# CY8C5888LTI_LP097 register map
File version: 0.1
CY8C58LP
Registers are 8-bit, read-write, no defined reset value unless marked. A register's access mark holds for its fields unless they carry their own. Offsets are from the block's base; lines under a group give offsets from that group; [hi:lo] are bit positions; {n}, {i} and the like mark numbered series; 'fields as' and 'values as' point back to an identical list; <NAME> marks a mode.

## Memory map
0x00000000 POT_VALUE — SAR ADC
0x00000000 Lights_Out_1_BUCK_DUTY
0x00000000 USB — USBFS
0x00000000 SleepTimer
0x00000000 RAMP_COMP
0x00000000 TRIANGLE_SEL_VDAC8
0x00000000 BRIGHTNESS_RAMP_VDAC8
0x40006467 CROSSFADE_VAL
0x40006469 Lights_Out_1_LED_STATUS
0x40006470 LIGHT_BRIGHTNESS_1
0x40006472 Lights_Out_1_LIGHT_COUNTER — Count7 debug registers
0x40006474 LIGHT_BRIGHTNESS_7
0x40006476 LIGHT_BRIGHTNESS_3
0x40006479 SLED_STATE_SEL
0x4000647B LIGHT_BRIGHTNESS_6
0x4000647D LIGHT_BRIGHTNESS_5
0x40006574 CROSSFADE_CTRL
0x40006576 LIGHT_BRIGHTNESS_2
0x40006578 LIGHT_BRIGHTNESS_4
0x4000657B HOT_LEDS

## CROSSFADE_VAL
Base 0x40006467
0x00 CROSSFADE_VAL_STATUS_REG
0x20 CROSSFADE_VAL_MASK_REG
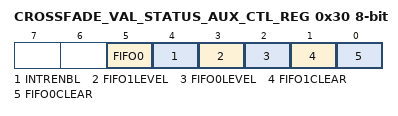
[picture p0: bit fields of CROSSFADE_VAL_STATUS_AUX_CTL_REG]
0x30 CROSSFADE_VAL_STATUS_AUX_CTL_REG
  [5] FIFO0 — FIFO0 clear
    1=ENABLED (Enable counter); 0=DISABLED (Disable counter)
  [4] INTRENBL — Enables or disables the Interrupt
    1=ENABLED (Interrupt enabled); 0=DISABLED (Interrupt disabled)
  [3] FIFO1LEVEL — FIFO level
    1=ENABLED (FIFO LVL: input mode: FIFO at least 1/2 empty; output mode: FIFO at least 1/2 full); 0=DISABLED (FIFO LVL: input mode: FIFO not full; output mode: FIFO not empty)
  [2] FIFO0LEVEL — FIFO level
    values as FIFO1LEVEL
  [1] FIFO1CLEAR — FIFO clear
    1=ENABLED (Clear FIFO state); 0=DISABLED (Normal FIFO operation)
  [0] FIFO0CLEAR — FIFO clear
    values as FIFO1CLEAR

## Lights_Out_1_LED_STATUS
Base 0x40006469
Registers as CROSSFADE_VAL (with CROSSFADE_VAL read as Lights_Out_1_LED_STATUS).

## POT_VALUE — SAR ADC
Base 0x00000000
0x40004614 SAR_TR0 — SAR trim register
{0x40005900+i} SAR_CSR{i} (i=0..6) — SAR status and control register {i}
0x40005B20 SAR_SW0 — SAR Analog Routing Register 0
{0x40005B20+i} SAR_SW{i} (i=2..4) — SAR Analog Routing Register {i}
0x40005B26 SAR_SW6 — SAR Analog Routing Register 6
0x40005B27 SAR_CLK — SAR Clock Selection Register
0x40005BA0 SAR_WRK 16-bit — SAR working register

## LIGHT_BRIGHTNESS_1
Base 0x40006470
0x00 LIGHT_BRIGHTNESS_1_CONTROL_REG

## LIGHT_BRIGHTNESS_2
Base 0x40006576
Registers as LIGHT_BRIGHTNESS_1 (with LIGHT_BRIGHTNESS_1 read as LIGHT_BRIGHTNESS_2).

## LIGHT_BRIGHTNESS_3
Base 0x40006476
Registers as LIGHT_BRIGHTNESS_1 (with LIGHT_BRIGHTNESS_1 read as LIGHT_BRIGHTNESS_3).

## LIGHT_BRIGHTNESS_4
Base 0x40006578
Registers as LIGHT_BRIGHTNESS_1 (with LIGHT_BRIGHTNESS_1 read as LIGHT_BRIGHTNESS_4).

## LIGHT_BRIGHTNESS_5
Base 0x4000647D
Registers as LIGHT_BRIGHTNESS_1 (with LIGHT_BRIGHTNESS_1 read as LIGHT_BRIGHTNESS_5).

## LIGHT_BRIGHTNESS_6
Base 0x4000647B
Registers as LIGHT_BRIGHTNESS_1 (with LIGHT_BRIGHTNESS_1 read as LIGHT_BRIGHTNESS_6).

## LIGHT_BRIGHTNESS_7
Base 0x40006474
Registers as LIGHT_BRIGHTNESS_1 (with LIGHT_BRIGHTNESS_1 read as LIGHT_BRIGHTNESS_7).

## CROSSFADE_CTRL
Base 0x40006574
Registers as LIGHT_BRIGHTNESS_1 (with LIGHT_BRIGHTNESS_1 read as CROSSFADE_CTRL).

## HOT_LEDS
Base 0x4000657B
Registers as LIGHT_BRIGHTNESS_1 (with LIGHT_BRIGHTNESS_1 read as HOT_LEDS).

## SLED_STATE_SEL
Base 0x40006479
Registers as LIGHT_BRIGHTNESS_1 (with LIGHT_BRIGHTNESS_1 read as SLED_STATE_SEL).

## Lights_Out_1_LIGHT_COUNTER — Count7 debug registers
Base 0x40006472
0x00 COUNT 7-bit — Count value register
0x10 PERIOD 7-bit — Count7 period register

## Lights_Out_1_BUCK_DUTY
Base 0x00000000
0x400043A3 Lights_Out_1_BUCK_DUTY_GLOBAL_ENABLE — PM.ACT.CFG
  [3:0] en_timer — Enable timer/counters.
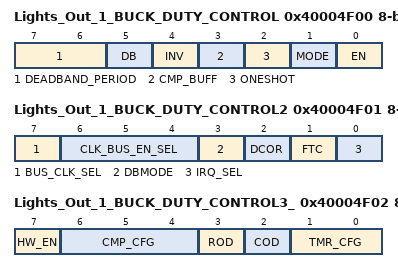
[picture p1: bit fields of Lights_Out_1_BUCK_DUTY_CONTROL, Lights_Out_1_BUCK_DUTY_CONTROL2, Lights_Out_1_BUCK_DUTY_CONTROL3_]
0x40004F00 Lights_Out_1_BUCK_DUTY_CONTROL — TMRx.CFG0
  [7:6] DEADBAND_PERIOD
  [5] DB — Deadband mode--Deadband phases phi1 and phi2 are outputted on CMP and TC output pins respectively.
    0=Timer (CMP and TC are output.); 1=Deadband (PHI1 (instead of CMP) and PHI2 (instead of TC) are output.)
  [4] INV — Invert sense of TIMEREN signal
  [3] CMP_BUFF — Buffer compare register. Compare register updates only on timer terminal count.
  [2] ONESHOT — Timer stops upon reaching stop condition defined by TMR_CFG bits. Can be restarted by asserting TIMER RESET or disabling and re-enabling block.
  [1] MODE — Mode. (0 = Timer; 1 = Comparator)
    0=Timer mode. CNT/CMP register holds timer count value.; 1=Comparator mode. CNT/CMP register holds comparator threshold value.
  [0] EN — Enables timer/comparator.
0x40004F01 Lights_Out_1_BUCK_DUTY_CONTROL2 — TMRx.CFG1
  [7] BUS_CLK_SEL — Bus Clock selection.
  [6:4] CLK_BUS_EN_SEL — Digital Global Clock selection.
  [3] DBMODE — Deadband mode (asynchronous/synchronous). CMP output pin is also affected when not in deadband mode (CFG0.DEADBAND).
  [2] DCOR — Disable Clear on Read (DCOR) of Status Register SR0.
  [1] FTC — First Terminal Count (FTC). Setting this bit forces a single pulse on the TC pin when first enabled.
    0=Disable_FTC (Disable the single cycle pulse, which signifies the timer is starting.); 1=Enable_FTC (Enable the single cycle pulse, which signifies the timer is starting.)
  [0] IRQ_SEL — Irq selection. (0 = raw interrupts; 1 = status register interrupts)
0x40004F02 Lights_Out_1_BUCK_DUTY_CONTROL3_ — TMRx.CFG2
  [7] HW_EN — When set Timer Enable controls counting.
  [6:4] CMP_CFG — Comparator configurations
    0=Equal (Compare Equal); 1=Less_than (Compare Less Than); 2=Less_than_or_equal (Compare Less Than or Equal .); 3=Greater (Compare Greater Than .); 4=Greater_than_or_equal (Compare Greater Than or Equal)
  [3] ROD — Reset On Disable (ROD). Resets internal state of output logic
  [2] COD — Clear On Disable (COD). Clears or gates outputs to zero.
  [1:0] TMR_CFG — Timer configuration (MODE = 0): 000 = Continuous; 001 = Pulsewidth; 010 = Period; 011 = Stop on IRQ
    0=Continuous (Timer runs while EN bit of CFG0 register is set to '1'.); 1=Pulsewidth (Timer runs from positive to negative edge of TIMEREN.); 2=Period (Timer runs from positive to positive edge of TIMEREN.); 3=Irq (Timer runs until IRQ.)
0x40004F04 Lights_Out_1_BUCK_DUTY_PERIOD — TMRx.PER0 - Assigned Period
0x40004F06 Lights_Out_1_BUCK_DUTY_COMPARE — TMRx.CNT_CMP0 - Assigned Compare Value
